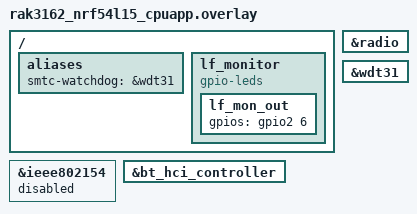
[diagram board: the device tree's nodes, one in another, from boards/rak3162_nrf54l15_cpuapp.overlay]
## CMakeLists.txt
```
# Copyright (c) 2026 RAKwireless Technology Limited
# SPDX-License-Identifier: Apache-2.0

cmake_minimum_required(VERSION 3.20.0)

find_package(Zephyr REQUIRED HINTS $ENV{ZEPHYR_BASE})

project(rak3162_hw_test)

target_include_directories(app PRIVATE
    src
)

target_sources(app PRIVATE
    src/main.c
    src/core/hw_app.c
    src/core/hw_console.c
    src/core/hw_led.c
    src/core/hw_xo_cap.c
    src/storage/hw_storage.c
    src/at/hw_at.c
    src/at/hw_at_lora.c
    src/at/hw_at_lorawan.c
    src/at/hw_at_test.c
    src/at/hw_at_ble_cw.c
    src/lora/hw_lora_p2p.c
    src/lora/hw_lorawan.c
)
```

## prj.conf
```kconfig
# Copyright (c) 2026 RAKwireless Technology Limited
# SPDX-License-Identifier: Apache-2.0

CONFIG_USE_SEGGER_RTT=n

CONFIG_LOG=y
CONFIG_LOG_FUNC_NAME_PREFIX_ERR=n
CONFIG_LOG_FUNC_NAME_PREFIX_WRN=n
CONFIG_LOG_FUNC_NAME_PREFIX_INF=n
CONFIG_LOG_FUNC_NAME_PREFIX_DBG=n
CONFIG_LOG_BACKEND_SHOW_COLOR=n
CONFIG_LOG_MODE_IMMEDIATE=y
CONFIG_BOOT_BANNER=n

CONFIG_SERIAL=y
CONFIG_CONSOLE=y
CONFIG_UART_CONSOLE=y
CONFIG_UART_ASYNC_API=y

CONFIG_GPIO=y
CONFIG_HWINFO=y
CONFIG_NRF_GRTC_TIMER=y
CONFIG_CLOCK_CONTROL=y
CONFIG_CLOCK_CONTROL_NRF=y
CONFIG_REGULATOR=y
CONFIG_REGULATOR_FIXED=y
CONFIG_I2C=y
CONFIG_SPI=y

CONFIG_PM_DEVICE=y
CONFIG_POWEROFF=y
CONFIG_REBOOT=y
CONFIG_WATCHDOG=n

CONFIG_MAIN_STACK_SIZE=4096
CONFIG_MAIN_THREAD_PRIORITY=-2
CONFIG_HEAP_MEM_POOL_SIZE=8192
# LoRaMAC TimerIrqHandler -> MacProcessNotify -> LoRaMacProcess runs here
CONFIG_SYSTEM_WORKQUEUE_STACK_SIZE=8192
CONFIG_STACK_SENTINEL=y
CONFIG_THREAD_STACK_INFO=y
CONFIG_THREAD_MONITOR=y
CONFIG_THREAD_NAME=y
CONFIG_EXTRA_EXCEPTION_INFO=y
CONFIG_FAULT_DUMP=2

CONFIG_BT=y
CONFIG_BT_BROADCASTER=y
CONFIG_BT_DEVICE_NAME="rak3162_hw_test"

# Zephyr LoRa + LoRaWAN (loramac-node); default AT+BAND=4 (EU868)
# Multiple regions enabled so AT+BAND can select before lorawan_start().
# AS923-2/3/4 and LA915 are not available in Zephyr.
CONFIG_LORA=y
CONFIG_LORAWAN=y
CONFIG_LORAMAC_REGION_EU868=y
CONFIG_LORAMAC_REGION_EU433=y
CONFIG_LORAMAC_REGION_CN470=y
CONFIG_LORAMAC_REGION_RU864=y
CONFIG_LORAMAC_REGION_IN865=y
CONFIG_LORAMAC_REGION_US915=y
CONFIG_LORAMAC_REGION_AU915=y
CONFIG_LORAMAC_REGION_KR920=y
CONFIG_LORAMAC_REGION_AS923=y

CONFIG_ENTROPY_GENERATOR=y
CONFIG_TEST_RANDOM_GENERATOR=y

CONFIG_PICOLIBC_USE_MODULE=n
CONFIG_NEWLIB_LIBC=y
CONFIG_NEWLIB_LIBC_NANO=y

CONFIG_FLASH=y
CONFIG_FLASH_MAP=y
CONFIG_NVS=y
CONFIG_SETTINGS=y
CONFIG_SETTINGS_NVS=y
```

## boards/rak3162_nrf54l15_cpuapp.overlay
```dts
/*
 * Copyright (c) 2026 RAKwireless Technology Limited
 * SPDX-License-Identifier: Apache-2.0
 */

/*
 * RAK3162 hardware test base overlay
 */

/ {
	aliases {
		smtc-watchdog = &wdt31;
	};

	/* GRTC LF monitor: MCU P2.06 (silk GPIO4), see AT+TEST=GRTC */
	lf_monitor {
		compatible = "gpio-leds";
		lf_mon_out: lf_mon_out {
			gpios = <&gpio2 6 GPIO_ACTIVE_HIGH>;
		};
	};
};

&radio {
	status = "okay";
};

&ieee802154 {
	status = "disabled";
};

&bt_hci_controller {
	status = "okay";
};

&wdt31 {
	status = "okay";
};
```

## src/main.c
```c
/*
 * Copyright (c) 2026 RAKwireless Technology Limited
 * SPDX-License-Identifier: Apache-2.0
 */

#include <zephyr/version.h>
#include <zephyr/kernel.h>
#include <zephyr/logging/log.h>
#include <zephyr/drivers/hwinfo.h>

#include "at/hw_at.h"
#include "core/hw_app.h"
#include "core/hw_console.h"
#include "core/hw_led.h"
#include "core/hw_xo_cap.h"
#include "lora/hw_lora_p2p.h"
#include "lora/hw_lorawan.h"
#include "storage/hw_storage.h"

LOG_MODULE_REGISTER(hw_main, LOG_LEVEL_INF);

static void log_reset_cause(void)
{
	uint32_t cause = 0U;
	int ret = hwinfo_get_reset_cause(&cause);

	if (ret == 0) {
		LOG_INF("Reset cause: 0x%08x", cause);
		(void)hwinfo_clear_reset_cause();
	}
}

int main(void)
{
	int ret;
	struct hw_runtime_cfg active_cfg;

	ret = hw_console_init();
	if (ret != 0) {
		LOG_ERR("Console init failed: %d", ret);
		return ret;
	}
	LOG_INF("Console init done");
	log_reset_cause();

	ret = hw_storage_init();
	if (ret != 0) {
		LOG_ERR("Storage init failed: %d", ret);
	} else {
		LOG_INF("Storage init done");
		hw_storage_get_active_cfg(&active_cfg);
		hw_runtime_apply_stored_caps(&active_cfg);
	}

	hw_lora_p2p_init();
	hw_lorawan_init();
	hw_at_init();
	LOG_INF("AT framework init done");

	/* RUI3 AT+JOIN Param2: auto-join on power up */
	hw_lorawan_autojoin_on_boot();

	ret = hw_led_start();
	if (ret != 0) {
		LOG_ERR("LED blink start failed: %d", ret);
	}

	ret = hw_app_start();
	if (ret != 0) {
		LOG_ERR("Runtime task start failed: %d", ret);
		return ret;
	}

	LOG_INF("zephyr_version: %s", KERNEL_VERSION_STRING);

	while (1) {
		k_sleep(K_SECONDS(1));
	}

	return 0;
}
```

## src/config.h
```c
/*
 * Copyright (c) 2026 RAKwireless Technology Limited
 * SPDX-License-Identifier: Apache-2.0
 */

#ifndef __CONFIG_H
#define __CONFIG_H


#define SOFTWARE_VERSION   "V_1.0.0"

#endif
```
